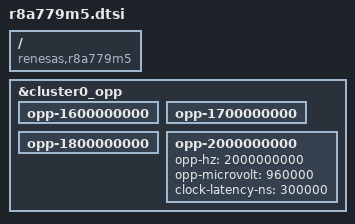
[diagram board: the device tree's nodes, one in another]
// SPDX-License-Identifier: GPL-2.0
/*
 * Device Tree Source for the R-Car M3Ne-2G (R8A779M5) SoC
 *
 * Copyright (C) 2021 Renesas Electronics Corp.
 */

#include "r8a77965.dtsi"

/ {
	compatible = "renesas,r8a779m5", "renesas,r8a77965";
};

&cluster0_opp {
	opp-1600000000 {
		/delete-property/turbo-mode;
	};
	opp-1700000000 {
		/delete-property/turbo-mode;
	};
	opp-1800000000 {
		/delete-property/turbo-mode;
	};
	opp-2000000000 {
		opp-hz = /bits/ 64 <2000000000>;
		opp-microvolt = <960000>;
		clock-latency-ns = <300000>;
	};
};
